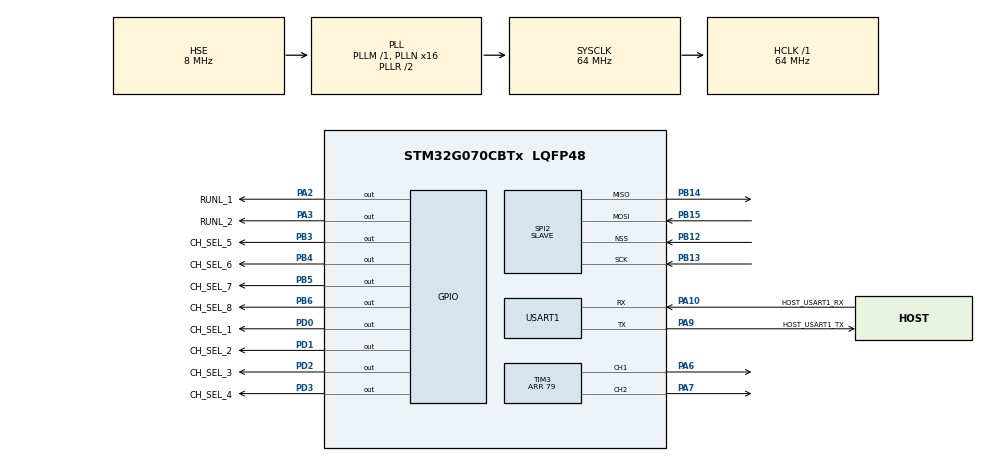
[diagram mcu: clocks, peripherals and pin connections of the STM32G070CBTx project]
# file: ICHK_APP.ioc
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Dma.Request0=TIM3_CH1
Dma.Request1=TIM3_CH2
Dma.Request2=USART1_RX
Dma.Request3=SPI2_RX
Dma.SPI2_RX.3.Direction=DMA_PERIPH_TO_MEMORY
Dma.SPI2_RX.3.EventEnable=DISABLE
Dma.SPI2_RX.3.Instance=DMA1_Channel4
Dma.SPI2_RX.3.MemDataAlignment=DMA_MDATAALIGN_BYTE
Dma.SPI2_RX.3.MemInc=DMA_MINC_ENABLE
Dma.SPI2_RX.3.Mode=DMA_CIRCULAR
Dma.SPI2_RX.3.PeriphDataAlignment=DMA_PDATAALIGN_BYTE
Dma.SPI2_RX.3.PeriphInc=DMA_PINC_DISABLE
Dma.SPI2_RX.3.Polarity=HAL_DMAMUX_REQ_GEN_RISING
Dma.SPI2_RX.3.Priority=DMA_PRIORITY_MEDIUM
Dma.SPI2_RX.3.RequestNumber=1
Dma.SPI2_RX.3.SignalID=NONE
Dma.SPI2_RX.3.SyncEnable=DISABLE
Dma.SPI2_RX.3.SyncPolarity=HAL_DMAMUX_SYNC_NO_EVENT
Dma.SPI2_RX.3.SyncRequestNumber=1
Dma.SPI2_RX.3.SyncSignalID=NONE
Dma.TIM3_CH1.0.Direction=DMA_MEMORY_TO_PERIPH
Dma.TIM3_CH1.0.EventEnable=DISABLE
Dma.TIM3_CH1.0.Instance=DMA1_Channel1
Dma.TIM3_CH1.0.MemDataAlignment=DMA_MDATAALIGN_WORD
Dma.TIM3_CH1.0.MemInc=DMA_MINC_ENABLE
Dma.TIM3_CH1.0.Mode=DMA_NORMAL
Dma.TIM3_CH1.0.PeriphDataAlignment=DMA_PDATAALIGN_WORD
Dma.TIM3_CH1.0.PeriphInc=DMA_PINC_DISABLE
Dma.TIM3_CH1.0.Polarity=HAL_DMAMUX_REQ_GEN_RISING
Dma.TIM3_CH1.0.Priority=DMA_PRIORITY_HIGH
Dma.TIM3_CH1.0.RequestNumber=1
Dma.TIM3_CH1.0.SignalID=NONE
Dma.TIM3_CH1.0.SyncEnable=DISABLE
Dma.TIM3_CH1.0.SyncPolarity=HAL_DMAMUX_SYNC_NO_EVENT
Dma.TIM3_CH1.0.SyncRequestNumber=1
Dma.TIM3_CH1.0.SyncSignalID=NONE
Dma.TIM3_CH2.1.Direction=DMA_MEMORY_TO_PERIPH
Dma.TIM3_CH2.1.EventEnable=DISABLE
Dma.TIM3_CH2.1.Instance=DMA1_Channel2
Dma.TIM3_CH2.1.MemDataAlignment=DMA_MDATAALIGN_WORD
Dma.TIM3_CH2.1.MemInc=DMA_MINC_ENABLE
Dma.TIM3_CH2.1.Mode=DMA_NORMAL
Dma.TIM3_CH2.1.PeriphDataAlignment=DMA_PDATAALIGN_WORD
Dma.TIM3_CH2.1.PeriphInc=DMA_PINC_DISABLE
Dma.TIM3_CH2.1.Polarity=HAL_DMAMUX_REQ_GEN_RISING
Dma.TIM3_CH2.1.Priority=DMA_PRIORITY_HIGH
Dma.TIM3_CH2.1.RequestNumber=1
Dma.TIM3_CH2.1.SignalID=NONE
Dma.TIM3_CH2.1.SyncEnable=DISABLE
Dma.TIM3_CH2.1.SyncPolarity=HAL_DMAMUX_SYNC_NO_EVENT
Dma.TIM3_CH2.1.SyncRequestNumber=1
Dma.TIM3_CH2.1.SyncSignalID=NONE
Dma.USART1_RX.2.Direction=DMA_PERIPH_TO_MEMORY
Dma.USART1_RX.2.EventEnable=DISABLE
Dma.USART1_RX.2.Instance=DMA1_Channel3
Dma.USART1_RX.2.MemDataAlignment=DMA_MDATAALIGN_BYTE
Dma.USART1_RX.2.MemInc=DMA_MINC_ENABLE
Dma.USART1_RX.2.Mode=DMA_CIRCULAR
Dma.USART1_RX.2.PeriphDataAlignment=DMA_PDATAALIGN_BYTE
Dma.USART1_RX.2.PeriphInc=DMA_PINC_DISABLE
Dma.USART1_RX.2.Polarity=HAL_DMAMUX_REQ_GEN_RISING
Dma.USART1_RX.2.Priority=DMA_PRIORITY_MEDIUM
Dma.USART1_RX.2.RequestNumber=1
Dma.USART1_RX.2.SignalID=NONE
Dma.USART1_RX.2.SyncEnable=DISABLE
Dma.USART1_RX.2.SyncPolarity=HAL_DMAMUX_SYNC_NO_EVENT
Dma.USART1_RX.2.SyncRequestNumber=1
Dma.USART1_RX.2.SyncSignalID=NONE
Mcu.Family=STM32G0
Mcu.Name=STM32G070CBTx
Mcu.Package=LQFP48
NVIC.DMA1_Ch4_7_DMAMUX1_OVR_IRQn=true\:0\:0\:false\:false\:true\:false\:true\:true
NVIC.DMA1_Channel1_IRQn=true\:0\:0\:false\:false\:true\:false\:true\:true
NVIC.DMA1_Channel2_3_IRQn=true\:0\:0\:false\:false\:true\:false\:true\:true
NVIC.SPI2_IRQn=true\:0\:0\:false\:false\:true\:true\:true\:true
NVIC.USART1_IRQn=true\:0\:0\:false\:false\:true\:true\:true\:true
PA10.GPIO_Label=HOST_USART1_RX
PA10.Mode=Asynchronous
PA10.Signal=USART1_RX
PA13.Mode=Serial_Wire
PA13.Signal=SYS_SWDIO
PA14-BOOT0.Mode=Serial_Wire
PA14-BOOT0.Signal=SYS_SWCLK
PA2.GPIO_Label=RUNL_1
PA2.Signal=GPIO_Output
PA3.GPIO_Label=RUNL_2
PA3.Signal=GPIO_Output
PA6.Signal=S_TIM3_CH1
PA7.Signal=S_TIM3_CH2
PA9.GPIO_Label=HOST_USART1_TX
PA9.Mode=Asynchronous
PA9.Signal=USART1_TX
PB12.Mode=NSS_Signal_Hard_Input
PB12.Signal=SPI2_NSS
PB13.Mode=Full_Duplex_Slave
PB13.Signal=SPI2_SCK
PB14.Mode=Full_Duplex_Slave
PB14.Signal=SPI2_MISO
PB15.Mode=Full_Duplex_Slave
PB15.Signal=SPI2_MOSI
PB3.GPIO_Label=CH_SEL_5
PB3.GPIO_Speed=GPIO_SPEED_FREQ_MEDIUM
PB3.Signal=GPIO_Output
PB4.GPIO_Label=CH_SEL_6
PB4.GPIO_Speed=GPIO_SPEED_FREQ_MEDIUM
PB4.Signal=GPIO_Output
PB5.GPIO_Label=CH_SEL_7
PB5.GPIO_Speed=GPIO_SPEED_FREQ_MEDIUM
PB5.Signal=GPIO_Output
PB6.GPIO_Label=CH_SEL_8
PB6.GPIO_Speed=GPIO_SPEED_FREQ_MEDIUM
PB6.Signal=GPIO_Output
PD0.GPIO_Label=CH_SEL_1
PD0.GPIO_Speed=GPIO_SPEED_FREQ_MEDIUM
PD0.Signal=GPIO_Output
PD1.GPIO_Label=CH_SEL_2
PD1.GPIO_Speed=GPIO_SPEED_FREQ_MEDIUM
PD1.Signal=GPIO_Output
PD2.GPIO_Label=CH_SEL_3
PD2.GPIO_Speed=GPIO_SPEED_FREQ_MEDIUM
PD2.Signal=GPIO_Output
PD3.GPIO_Label=CH_SEL_4
PD3.GPIO_Speed=GPIO_SPEED_FREQ_MEDIUM
PD3.Signal=GPIO_Output
PF0-OSC_IN\ (PF0).Mode=HSE-External-Oscillator
PF0-OSC_IN\ (PF0).Signal=RCC_OSC_IN
PF1-OSC_OUT\ (PF1).Mode=HSE-External-Oscillator
PF1-OSC_OUT\ (PF1).Signal=RCC_OSC_OUT
ProjectManager.HeapSize=0x200
ProjectManager.StackSize=0x400
ProjectManager.TargetToolchain=STM32CubeIDE
RCC.ADCFreq_Value=64000000
RCC.AHBFreq_Value=64000000
RCC.CortexFreq_Value=64000000
RCC.EXTERNAL_CLOCK_VALUE=48000
RCC.HCLKFreq_Value=64000000
RCC.HSE_VALUE=8000000
RCC.HSI_VALUE=16000000
RCC.LSE_VALUE=32768
RCC.PLLN=16
RCC.PLLSourceVirtual=RCC_PLLSOURCE_HSE
RCC.SYSCLKFreq_VALUE=64000000
RCC.SYSCLKSource=RCC_SYSCLKSOURCE_PLLCLK
RCC.VCOOutputFreq_Value=128000000
SH.S_TIM3_CH1.0=TIM3_CH1,PWM Generation1 CH1
SH.S_TIM3_CH2.0=TIM3_CH2,PWM Generation2 CH2
SPI2.DataSize=SPI_DATASIZE_8BIT
SPI2.Direction=SPI_DIRECTION_2LINES
SPI2.Mode=SPI_MODE_SLAVE
SPI2.VirtualNSS=VM_NSSHARD
SPI2.VirtualType=VM_SLAVE
TIM3.AutoReloadPreload=TIM_AUTORELOAD_PRELOAD_ENABLE
TIM3.Channel-PWM\ Generation1\ CH1=TIM_CHANNEL_1
TIM3.Channel-PWM\ Generation2\ CH2=TIM_CHANNEL_2
TIM3.Period=79
USART1.VirtualMode-Asynchronous=VM_ASYNC
VP_TIM3_VS_ClockSourceINT.Mode=Internal
board=custom

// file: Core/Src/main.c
/* USER CODE BEGIN Header */
/**
  ******************************************************************************
  * @file           : main.c
  * @brief          : Main program body
  ******************************************************************************
  * @attention
  *
  * Copyright (c) 2026 STMicroelectronics.
  * All rights reserved.
  *
  * This software is licensed under terms that can be found in the LICENSE file
  * in the root directory of this software component.
  * If no LICENSE file comes with this software, it is provided AS-IS.
  *
  ******************************************************************************
  */
/* USER CODE END Header */
#include "main.h"

/* USER CODE BEGIN Includes */
#include "host_protocol.h"
#include "led_driver.h"
#include "status_led.h"
/* USER CODE END Includes */

SPI_HandleTypeDef hspi2;
DMA_HandleTypeDef hdma_spi2_rx;

TIM_HandleTypeDef htim3;
DMA_HandleTypeDef hdma_tim3_ch1;
DMA_HandleTypeDef hdma_tim3_ch2;

UART_HandleTypeDef huart1;
DMA_HandleTypeDef hdma_usart1_rx;

void SystemClock_Config(void);
static void MX_GPIO_Init(void);
static void MX_DMA_Init(void);
static void MX_SPI2_Init(void);
static void MX_USART1_UART_Init(void);
static void MX_TIM3_Init(void);

int main(void)
{

  /* USER CODE BEGIN 1 */
	SCB->VTOR = 0x08004000UL;
  /* USER CODE END 1 */

  /* MCU Configuration--------------------------------------------------------*/

  /* Reset of all peripherals, Initializes the Flash interface and the Systick. */
  HAL_Init();

  /* Configure the system clock */
  SystemClock_Config();

  /* Initialize all configured peripherals */
  MX_GPIO_Init();
  MX_DMA_Init();
  MX_SPI2_Init();
  MX_USART1_UART_Init();
  MX_TIM3_Init();
  /* USER CODE BEGIN 2 */
  HostProtocol_Init();
  LED_DriverInit();
  /* USER CODE END 2 */

  /* Infinite loop */
  /* USER CODE BEGIN WHILE */
  while (1)
  {
    HostProtocol_Poll();
    LED_DriverPoll();
	StatusLed_ActivityPoll();	// 이 5Hz로 토글
	StatusLed_HeartbeatPoll();
	__WFI();   // 여기서 멈춰있다가, 다음 인터럽트(SysTick 등)가 오면 깨어남
    /* USER CODE END WHILE */

  }
}

void SystemClock_Config(void)
{
  RCC_OscInitTypeDef RCC_OscInitStruct = {0};
  RCC_ClkInitTypeDef RCC_ClkInitStruct = {0};

  /** Configure the main internal regulator output voltage
  */
  HAL_PWREx_ControlVoltageScaling(PWR_REGULATOR_VOLTAGE_SCALE1);

  /** Initializes the RCC Oscillators according to the specified parameters
  * in the RCC_OscInitTypeDef structure.
  */
  RCC_OscInitStruct.OscillatorType = RCC_OSCILLATORTYPE_HSE;
  RCC_OscInitStruct.HSEState = RCC_HSE_ON;
  RCC_OscInitStruct.PLL.PLLState = RCC_PLL_ON;
  RCC_OscInitStruct.PLL.PLLSource = RCC_PLLSOURCE_HSE;
  RCC_OscInitStruct.PLL.PLLM = RCC_PLLM_DIV1;
  RCC_OscInitStruct.PLL.PLLN = 16;
  RCC_OscInitStruct.PLL.PLLP = RCC_PLLP_DIV2;
  RCC_OscInitStruct.PLL.PLLR = RCC_PLLR_DIV2;
  if (HAL_RCC_OscConfig(&RCC_OscInitStruct) != HAL_OK)
  {
    Error_Handler();
  }

  /** Initializes the CPU, AHB and APB buses clocks
  */
  RCC_ClkInitStruct.ClockType = RCC_CLOCKTYPE_HCLK|RCC_CLOCKTYPE_SYSCLK
                              |RCC_CLOCKTYPE_PCLK1;
  RCC_ClkInitStruct.SYSCLKSource = RCC_SYSCLKSOURCE_PLLCLK;
  RCC_ClkInitStruct.AHBCLKDivider = RCC_SYSCLK_DIV1;
  RCC_ClkInitStruct.APB1CLKDivider = RCC_HCLK_DIV1;

  if (HAL_RCC_ClockConfig(&RCC_ClkInitStruct, FLASH_LATENCY_2) != HAL_OK)
  {
    Error_Handler();
  }
}

static void MX_SPI2_Init(void)
{

  /* SPI2 parameter configuration*/
  hspi2.Instance = SPI2;
  hspi2.Init.Mode = SPI_MODE_SLAVE;
  hspi2.Init.Direction = SPI_DIRECTION_2LINES;
  hspi2.Init.DataSize = SPI_DATASIZE_8BIT;
  hspi2.Init.CLKPolarity = SPI_POLARITY_LOW;
  hspi2.Init.CLKPhase = SPI_PHASE_1EDGE;
  hspi2.Init.NSS = SPI_NSS_HARD_INPUT;
  hspi2.Init.FirstBit = SPI_FIRSTBIT_MSB;
  hspi2.Init.TIMode = SPI_TIMODE_DISABLE;
  hspi2.Init.CRCCalculation = SPI_CRCCALCULATION_DISABLE;
  hspi2.Init.CRCPolynomial = 7;
  hspi2.Init.CRCLength = SPI_CRC_LENGTH_DATASIZE;
  hspi2.Init.NSSPMode = SPI_NSS_PULSE_DISABLE;
  if (HAL_SPI_Init(&hspi2) != HAL_OK)
  {
    Error_Handler();
  }

}

static void MX_TIM3_Init(void)
{

  TIM_ClockConfigTypeDef sClockSourceConfig = {0};
  TIM_MasterConfigTypeDef sMasterConfig = {0};
  TIM_OC_InitTypeDef sConfigOC = {0};

  htim3.Instance = TIM3;
  htim3.Init.Prescaler = 0;
  htim3.Init.CounterMode = TIM_COUNTERMODE_UP;
  htim3.Init.Period = 79;
  htim3.Init.ClockDivision = TIM_CLOCKDIVISION_DIV1;
  htim3.Init.AutoReloadPreload = TIM_AUTORELOAD_PRELOAD_ENABLE;
  if (HAL_TIM_Base_Init(&htim3) != HAL_OK)
  {
    Error_Handler();
  }
  sClockSourceConfig.ClockSource = TIM_CLOCKSOURCE_INTERNAL;
  if (HAL_TIM_ConfigClockSource(&htim3, &sClockSourceConfig) != HAL_OK)
  {
    Error_Handler();
  }
  if (HAL_TIM_PWM_Init(&htim3) != HAL_OK)
  {
    Error_Handler();
  }
  sMasterConfig.MasterOutputTrigger = TIM_TRGO_RESET;
  sMasterConfig.MasterSlaveMode = TIM_MASTERSLAVEMODE_DISABLE;
  if (HAL_TIMEx_MasterConfigSynchronization(&htim3, &sMasterConfig) != HAL_OK)
  {
    Error_Handler();
  }
  sConfigOC.OCMode = TIM_OCMODE_PWM1;
  sConfigOC.Pulse = 0;
  sConfigOC.OCPolarity = TIM_OCPOLARITY_HIGH;
  sConfigOC.OCFastMode = TIM_OCFAST_DISABLE;
  if (HAL_TIM_PWM_ConfigChannel(&htim3, &sConfigOC, TIM_CHANNEL_1) != HAL_OK)
  {
    Error_Handler();
  }
  if (HAL_TIM_PWM_ConfigChannel(&htim3, &sConfigOC, TIM_CHANNEL_2) != HAL_OK)
  {
    Error_Handler();
  }
  HAL_TIM_MspPostInit(&htim3);

}

static void MX_USART1_UART_Init(void)
{

  huart1.Instance = USART1;
  huart1.Init.BaudRate = 115200;
  huart1.Init.WordLength = UART_WORDLENGTH_8B;
  huart1.Init.StopBits = UART_STOPBITS_1;
  huart1.Init.Parity = UART_PARITY_NONE;
  huart1.Init.Mode = UART_MODE_TX_RX;
  huart1.Init.HwFlowCtl = UART_HWCONTROL_NONE;
  huart1.Init.OverSampling = UART_OVERSAMPLING_16;
  huart1.Init.OneBitSampling = UART_ONE_BIT_SAMPLE_DISABLE;
  huart1.Init.ClockPrescaler = UART_PRESCALER_DIV1;
  huart1.AdvancedInit.AdvFeatureInit = UART_ADVFEATURE_NO_INIT;
  if (HAL_UART_Init(&huart1) != HAL_OK)
  {
    Error_Handler();
  }
  if (HAL_UARTEx_SetTxFifoThreshold(&huart1, UART_TXFIFO_THRESHOLD_1_8) != HAL_OK)
  {
    Error_Handler();
  }
  if (HAL_UARTEx_SetRxFifoThreshold(&huart1, UART_RXFIFO_THRESHOLD_1_8) != HAL_OK)
  {
    Error_Handler();
  }
  if (HAL_UARTEx_DisableFifoMode(&huart1) != HAL_OK)
  {
    Error_Handler();
  }

}

static void MX_DMA_Init(void)
{

  /* DMA controller clock enable */
  __HAL_RCC_DMA1_CLK_ENABLE();

  /* DMA interrupt init */
  /* DMA1_Channel1_IRQn interrupt configuration */
  HAL_NVIC_SetPriority(DMA1_Channel1_IRQn, 0, 0);
  HAL_NVIC_EnableIRQ(DMA1_Channel1_IRQn);
  /* DMA1_Channel2_3_IRQn interrupt configuration */
  HAL_NVIC_SetPriority(DMA1_Channel2_3_IRQn, 0, 0);
  HAL_NVIC_EnableIRQ(DMA1_Channel2_3_IRQn);
  /* DMA1_Ch4_7_DMAMUX1_OVR_IRQn interrupt configuration */
  HAL_NVIC_SetPriority(DMA1_Ch4_7_DMAMUX1_OVR_IRQn, 0, 0);
  HAL_NVIC_EnableIRQ(DMA1_Ch4_7_DMAMUX1_OVR_IRQn);

}

static void MX_GPIO_Init(void)
{
  GPIO_InitTypeDef GPIO_InitStruct = {0};

  /* GPIO Ports Clock Enable */
  __HAL_RCC_GPIOF_CLK_ENABLE();
  __HAL_RCC_GPIOA_CLK_ENABLE();
  __HAL_RCC_GPIOB_CLK_ENABLE();
  __HAL_RCC_GPIOD_CLK_ENABLE();

  /*Configure GPIO pin Output Level */
  HAL_GPIO_WritePin(GPIOA, RUNL_1_Pin|RUNL_2_Pin, GPIO_PIN_RESET);

  /*Configure GPIO pin Output Level */
  HAL_GPIO_WritePin(GPIOD, CH_SEL_1_Pin|CH_SEL_2_Pin|CH_SEL_3_Pin|CH_SEL_4_Pin, GPIO_PIN_RESET);

  /*Configure GPIO pin Output Level */
  HAL_GPIO_WritePin(GPIOB, CH_SEL_5_Pin|CH_SEL_6_Pin|CH_SEL_7_Pin|CH_SEL_8_Pin, GPIO_PIN_RESET);

  /*Configure GPIO pins : RUNL_1_Pin RUNL_2_Pin */
  GPIO_InitStruct.Pin = RUNL_1_Pin|RUNL_2_Pin;
  GPIO_InitStruct.Mode = GPIO_MODE_OUTPUT_PP;
  GPIO_InitStruct.Pull = GPIO_NOPULL;
  GPIO_InitStruct.Speed = GPIO_SPEED_FREQ_LOW;
  HAL_GPIO_Init(GPIOA, &GPIO_InitStruct);

  /*Configure GPIO pins : CH_SEL_1_Pin CH_SEL_2_Pin CH_SEL_3_Pin CH_SEL_4_Pin */
  GPIO_InitStruct.Pin = CH_SEL_1_Pin|CH_SEL_2_Pin|CH_SEL_3_Pin|CH_SEL_4_Pin;
  GPIO_InitStruct.Mode = GPIO_MODE_OUTPUT_PP;
  GPIO_InitStruct.Pull = GPIO_NOPULL;
  GPIO_InitStruct.Speed = GPIO_SPEED_FREQ_MEDIUM;
  HAL_GPIO_Init(GPIOD, &GPIO_InitStruct);

  /*Configure GPIO pins : CH_SEL_5_Pin CH_SEL_6_Pin CH_SEL_7_Pin CH_SEL_8_Pin */
  GPIO_InitStruct.Pin = CH_SEL_5_Pin|CH_SEL_6_Pin|CH_SEL_7_Pin|CH_SEL_8_Pin;
  GPIO_InitStruct.Mode = GPIO_MODE_OUTPUT_PP;
  GPIO_InitStruct.Pull = GPIO_NOPULL;
  GPIO_InitStruct.Speed = GPIO_SPEED_FREQ_MEDIUM;
  HAL_GPIO_Init(GPIOB, &GPIO_InitStruct);

}

void Error_Handler(void)
{
  __disable_irq();
  while (1)
  {
  }
}
